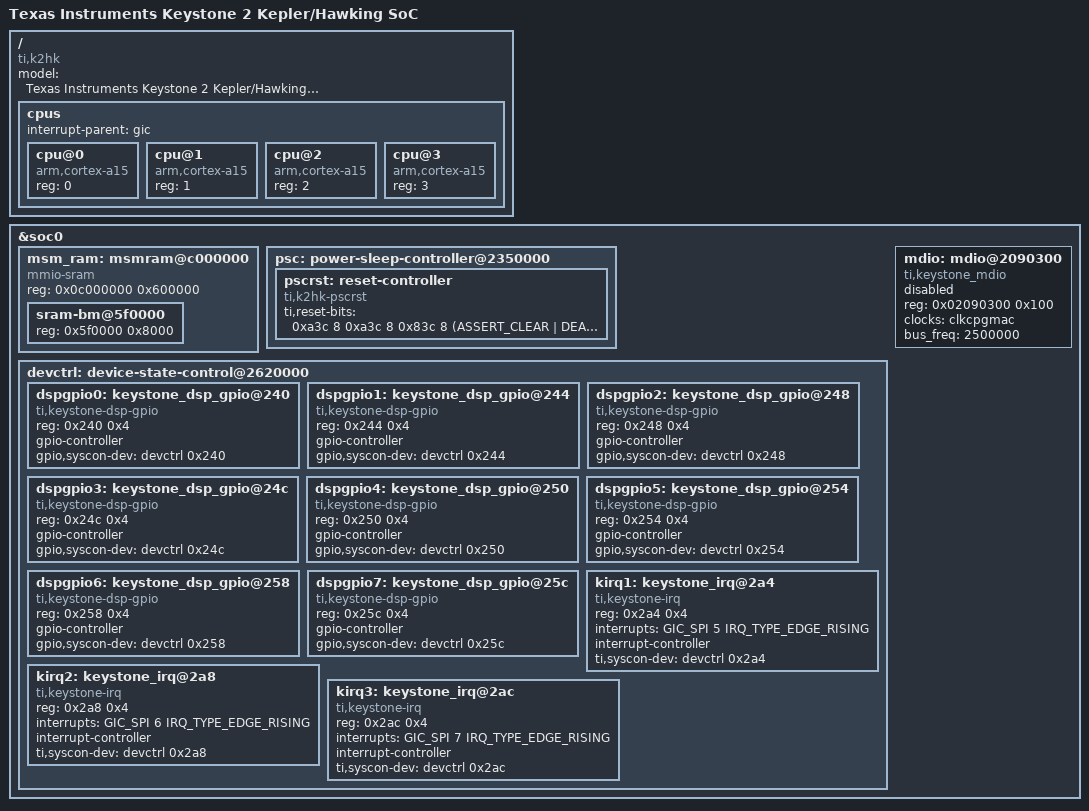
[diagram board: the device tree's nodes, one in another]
// SPDX-License-Identifier: GPL-2.0
/*
 * Keystone 2 Kepler/Hawking soc specific device tree
 *
 * Copyright (C) 2013-2017 Texas Instruments Incorporated - http://www.ti.com/
 */

#include <dt-bindings/reset/ti-syscon.h>

/ {
	compatible = "ti,k2hk", "ti,keystone";
	model = "Texas Instruments Keystone 2 Kepler/Hawking SoC";

	cpus {
		#address-cells = <1>;
		#size-cells = <0>;

		interrupt-parent = <&gic>;

		cpu@0 {
			compatible = "arm,cortex-a15";
			device_type = "cpu";
			reg = <0>;
		};

		cpu@1 {
			compatible = "arm,cortex-a15";
			device_type = "cpu";
			reg = <1>;
		};

		cpu@2 {
			compatible = "arm,cortex-a15";
			device_type = "cpu";
			reg = <2>;
		};

		cpu@3 {
			compatible = "arm,cortex-a15";
			device_type = "cpu";
			reg = <3>;
		};
	};
};

&soc0 {
		/include/ "keystone-agib-clocks.dtsi"

		msm_ram: msmram@c000000 {
			compatible = "mmio-sram";
			reg = <0x0c000000 0x600000>;
			ranges = <0x0 0x0c000000 0x600000>;
			#address-cells = <1>;
			#size-cells = <1>;

			sram-bm@5f0000 {
				reg = <0x5f0000 0x8000>;
			};
		};

		psc: power-sleep-controller@2350000 {
			pscrst: reset-controller {
				compatible = "ti,k2hk-pscrst", "ti,syscon-reset";
				#reset-cells = <1>;

				ti,reset-bits = <
					0xa3c 8 0xa3c 8 0x83c 8 (ASSERT_CLEAR | DEASSERT_SET | STATUS_CLEAR) /* 0: dsp0 */
					0xa40 8 0xa40 8 0x840 8 (ASSERT_CLEAR | DEASSERT_SET | STATUS_CLEAR) /* 1: dsp1 */
					0xa44 8 0xa44 8 0x844 8 (ASSERT_CLEAR | DEASSERT_SET | STATUS_CLEAR) /* 2: dsp2 */
					0xa48 8 0xa48 8 0x848 8 (ASSERT_CLEAR | DEASSERT_SET | STATUS_CLEAR) /* 3: dsp3 */
					0xa4c 8 0xa4c 8 0x84c 8 (ASSERT_CLEAR | DEASSERT_SET | STATUS_CLEAR) /* 4: dsp4 */
					0xa50 8 0xa50 8 0x850 8 (ASSERT_CLEAR | DEASSERT_SET | STATUS_CLEAR) /* 5: dsp5 */
					0xa54 8 0xa54 8 0x854 8 (ASSERT_CLEAR | DEASSERT_SET | STATUS_CLEAR) /* 6: dsp6 */
					0xa58 8 0xa58 8 0x858 8 (ASSERT_CLEAR | DEASSERT_SET | STATUS_CLEAR) /* 7: dsp7 */
				>;
			};
		};

		devctrl: device-state-control@2620000 {
			dspgpio0: keystone_dsp_gpio@240 {
				compatible = "ti,keystone-dsp-gpio";
				reg = <0x240 0x4>;
				gpio-controller;
				#gpio-cells = <2>;
				gpio,syscon-dev = <&devctrl 0x240>;
			};

			dspgpio1: keystone_dsp_gpio@244 {
				compatible = "ti,keystone-dsp-gpio";
				reg = <0x244 0x4>;
				gpio-controller;
				#gpio-cells = <2>;
				gpio,syscon-dev = <&devctrl 0x244>;
			};

			dspgpio2: keystone_dsp_gpio@248 {
				compatible = "ti,keystone-dsp-gpio";
				reg = <0x248 0x4>;
				gpio-controller;
				#gpio-cells = <2>;
				gpio,syscon-dev = <&devctrl 0x248>;
			};

			dspgpio3: keystone_dsp_gpio@24c {
				compatible = "ti,keystone-dsp-gpio";
				reg = <0x24c 0x4>;
				gpio-controller;
				#gpio-cells = <2>;
				gpio,syscon-dev = <&devctrl 0x24c>;
			};

			dspgpio4: keystone_dsp_gpio@250 {
				compatible = "ti,keystone-dsp-gpio";
				reg = <0x250 0x4>;
				gpio-controller;
				#gpio-cells = <2>;
				gpio,syscon-dev = <&devctrl 0x250>;
			};

			dspgpio5: keystone_dsp_gpio@254 {
				compatible = "ti,keystone-dsp-gpio";
				reg = <0x254 0x4>;
				gpio-controller;
				#gpio-cells = <2>;
				gpio,syscon-dev = <&devctrl 0x254>;
			};

			dspgpio6: keystone_dsp_gpio@258 {
				compatible = "ti,keystone-dsp-gpio";
				reg = <0x258 0x4>;
				gpio-controller;
				#gpio-cells = <2>;
				gpio,syscon-dev = <&devctrl 0x258>;
			};

			dspgpio7: keystone_dsp_gpio@25c {
				compatible = "ti,keystone-dsp-gpio";
				reg = <0x25c 0x4>;
				gpio-controller;
				#gpio-cells = <2>;
				gpio,syscon-dev = <&devctrl 0x25c>;
			};

			kirq1: keystone_irq@2a4 {
				compatible = "ti,keystone-irq";
				reg = <0x2a4 0x4>;
				interrupts = <GIC_SPI 5 IRQ_TYPE_EDGE_RISING>;
				interrupt-controller;
				#interrupt-cells = <1>;
				ti,syscon-dev = <&devctrl 0x2a4>;
			};

			kirq2: keystone_irq@2a8 {
				compatible = "ti,keystone-irq";
				reg = <0x2a8 0x4>;
				interrupts = <GIC_SPI 6 IRQ_TYPE_EDGE_RISING>;
				interrupt-controller;
				#interrupt-cells = <1>;
				ti,syscon-dev = <&devctrl 0x2a8>;
			};

			kirq3: keystone_irq@2ac {
				compatible = "ti,keystone-irq";
				reg = <0x2ac 0x4>;
				interrupts = <GIC_SPI 7 IRQ_TYPE_EDGE_RISING>;
				interrupt-controller;
				#interrupt-cells = <1>;
				ti,syscon-dev = <&devctrl 0x2ac>;
			};
		};

		mdio: mdio@2090300 {
			compatible	= "ti,keystone_mdio", "ti,davinci_mdio";
			#address-cells = <1>;
			#size-cells = <0>;
			reg = <0x02090300 0x100>;
			status = "disabled";
			clocks = <&clkcpgmac>;
			clock-names = "fck";
			bus_freq	= <2500000>;
		};
		/include/ "keystone-agib-pktdma.dtsi"
		/include/ "keystone-agib-netcp.dtsi"
};
